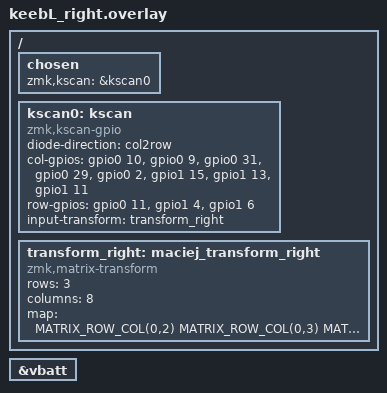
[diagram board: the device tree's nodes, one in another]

/* nice!nano v2 right half: COL2ROW, 3 rows x 8 cols */
#include <dt-bindings/zmk/matrix_transform.h>

&vbatt { status = "okay"; };

/ {
    chosen { zmk,kscan = &kscan0; }

    kscan0: kscan {
        compatible = "zmk,kscan-gpio";
        diode-direction = "col2row";

        /* Right side column pins (from KMK right col_pins) */
        col-gpios = <&gpio0 10 GPIO_ACTIVE_HIGH>,  /* P0.10 */
                    <&gpio0  9 GPIO_ACTIVE_HIGH>,  /* P0.09 */
                    <&gpio0 31 GPIO_ACTIVE_HIGH>,  /* P0.31 */
                    <&gpio0 29 GPIO_ACTIVE_HIGH>,  /* P0.29 */
                    <&gpio0  2 GPIO_ACTIVE_HIGH>,  /* P0.02 */
                    <&gpio1 15 GPIO_ACTIVE_HIGH>,  /* P1.15 */
                    <&gpio1 13 GPIO_ACTIVE_HIGH>,  /* P1.13 */
                    <&gpio1 11 GPIO_ACTIVE_HIGH>;  /* P1.11 */

        /* Right side row pins (from KMK right row_pins) */
        row-gpios = <&gpio0 11 (GPIO_ACTIVE_HIGH | GPIO_PULL_UP)>,  /* P0.11 */
                    <&gpio1  4 (GPIO_ACTIVE_HIGH | GPIO_PULL_UP)>,  /* P1.04 */
                    <&gpio1  6 (GPIO_ACTIVE_HIGH | GPIO_PULL_UP)>;  /* P1.06 */
    };
};

&kscan0 { input-transform = <&transform_right>; };

/ {
    /* Map 20 logical RIGHT keys (6..11, 18..23, 32..39) to physical 3x8 */
    transform_right: maciej_transform_right {
        compatible = "zmk,matrix-transform";
        rows = <3>;
        columns = <8>;
        map = <
            /* Row1 R: logical 6..11 -> physical indices 26..31 (local row0 col2..7) */
            MATRIX_ROW_COL(0,2) MATRIX_ROW_COL(0,3) MATRIX_ROW_COL(0,4)
            MATRIX_ROW_COL(0,5) MATRIX_ROW_COL(0,6) MATRIX_ROW_COL(0,7)

            /* Row2 R: logical 18..23 -> physical indices 34..39 (local row1 col2..7) */
            MATRIX_ROW_COL(1,2) MATRIX_ROW_COL(1,3) MATRIX_ROW_COL(1,4)
            MATRIX_ROW_COL(1,5) MATRIX_ROW_COL(1,6) MATRIX_ROW_COL(1,7)

            /* Row3 R: logical 32..39 -> physical indices 40..47 (local row2 col0..7) */
            MATRIX_ROW_COL(2,0) MATRIX_ROW_COL(2,1) MATRIX_ROW_COL(2,2) MATRIX_ROW_COL(2,3)
            MATRIX_ROW_COL(2,4) MATRIX_ROW_COL(2,5) MATRIX_ROW_COL(2,6) MATRIX_ROW_COL(2,7)
        >;
    };
};
